# MOTOR register map
Registers are 32-bit, access not given, no defined reset value unless marked. A register's access mark holds for its fields unless they carry their own. Addresses are absolute; registers are grouped by the start of their names; [hi:lo] are bit positions; {n}, {i} and the like mark numbered series.

## FILTER
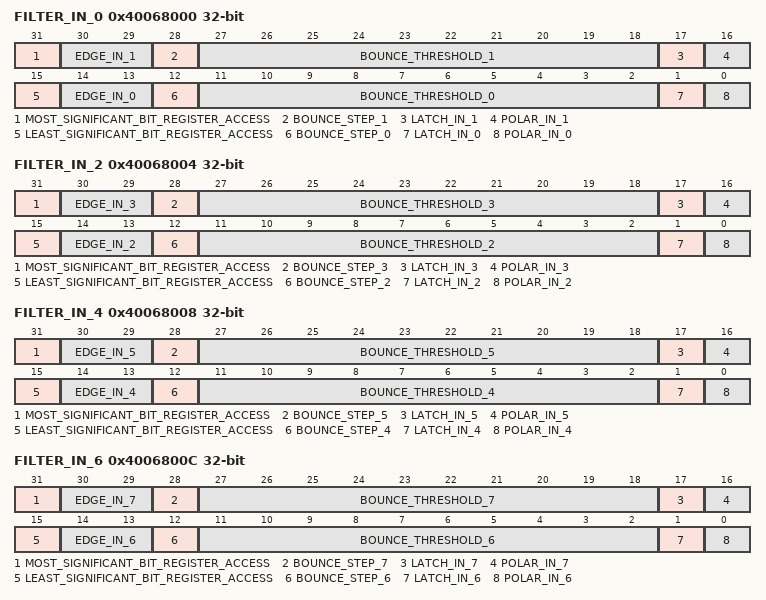
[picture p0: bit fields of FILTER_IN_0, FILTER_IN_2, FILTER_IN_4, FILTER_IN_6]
0x40068000 FILTER_IN_0
  [31] MOST_SIGNIFICANT_BIT_REGISTER_ACCESS, [30:29] EDGE_IN_1, [28] BOUNCE_STEP_1, [27:18] BOUNCE_THRESHOLD_1, [17] LATCH_IN_1, [16] POLAR_IN_1, [15] LEAST_SIGNIFICANT_BIT_REGISTER_ACCESS, [14:13] EDGE_IN_0, [12] BOUNCE_STEP_0, [11:2] BOUNCE_THRESHOLD_0, [1] LATCH_IN_0, [0] POLAR_IN_0
0x40068004 FILTER_IN_2
  [31] MOST_SIGNIFICANT_BIT_REGISTER_ACCESS, [30:29] EDGE_IN_3, [28] BOUNCE_STEP_3, [27:18] BOUNCE_THRESHOLD_3, [17] LATCH_IN_3, [16] POLAR_IN_3, [15] LEAST_SIGNIFICANT_BIT_REGISTER_ACCESS, [14:13] EDGE_IN_2, [12] BOUNCE_STEP_2, [11:2] BOUNCE_THRESHOLD_2, [1] LATCH_IN_2, [0] POLAR_IN_2
0x40068008 FILTER_IN_4
  [31] MOST_SIGNIFICANT_BIT_REGISTER_ACCESS, [30:29] EDGE_IN_5, [28] BOUNCE_STEP_5, [27:18] BOUNCE_THRESHOLD_5, [17] LATCH_IN_5, [16] POLAR_IN_5, [15] LEAST_SIGNIFICANT_BIT_REGISTER_ACCESS, [14:13] EDGE_IN_4, [12] BOUNCE_STEP_4, [11:2] BOUNCE_THRESHOLD_4, [1] LATCH_IN_4, [0] POLAR_IN_4
0x4006800C FILTER_IN_6
  [31] MOST_SIGNIFICANT_BIT_REGISTER_ACCESS, [30:29] EDGE_IN_7, [28] BOUNCE_STEP_7, [27:18] BOUNCE_THRESHOLD_7, [17] LATCH_IN_7, [16] POLAR_IN_7, [15] LEAST_SIGNIFICANT_BIT_REGISTER_ACCESS, [14:13] EDGE_IN_6, [12] BOUNCE_STEP_6, [11:2] BOUNCE_THRESHOLD_6, [1] LATCH_IN_6, [0] POLAR_IN_6
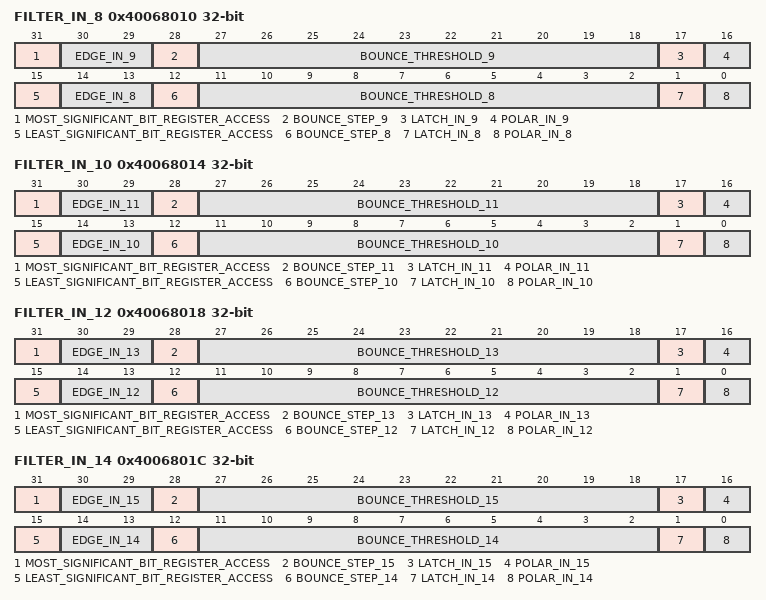
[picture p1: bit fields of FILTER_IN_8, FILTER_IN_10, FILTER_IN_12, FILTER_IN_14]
0x40068010 FILTER_IN_8
  [31] MOST_SIGNIFICANT_BIT_REGISTER_ACCESS, [30:29] EDGE_IN_9, [28] BOUNCE_STEP_9, [27:18] BOUNCE_THRESHOLD_9, [17] LATCH_IN_9, [16] POLAR_IN_9, [15] LEAST_SIGNIFICANT_BIT_REGISTER_ACCESS, [14:13] EDGE_IN_8, [12] BOUNCE_STEP_8, [11:2] BOUNCE_THRESHOLD_8, [1] LATCH_IN_8, [0] POLAR_IN_8
0x40068014 FILTER_IN_10
  [31] MOST_SIGNIFICANT_BIT_REGISTER_ACCESS, [30:29] EDGE_IN_11, [28] BOUNCE_STEP_11, [27:18] BOUNCE_THRESHOLD_11, [17] LATCH_IN_11, [16] POLAR_IN_11, [15] LEAST_SIGNIFICANT_BIT_REGISTER_ACCESS, [14:13] EDGE_IN_10, [12] BOUNCE_STEP_10, [11:2] BOUNCE_THRESHOLD_10, [1] LATCH_IN_10, [0] POLAR_IN_10
0x40068018 FILTER_IN_12
  [31] MOST_SIGNIFICANT_BIT_REGISTER_ACCESS, [30:29] EDGE_IN_13, [28] BOUNCE_STEP_13, [27:18] BOUNCE_THRESHOLD_13, [17] LATCH_IN_13, [16] POLAR_IN_13, [15] LEAST_SIGNIFICANT_BIT_REGISTER_ACCESS, [14:13] EDGE_IN_12, [12] BOUNCE_STEP_12, [11:2] BOUNCE_THRESHOLD_12, [1] LATCH_IN_12, [0] POLAR_IN_12
0x4006801C FILTER_IN_14
  [31] MOST_SIGNIFICANT_BIT_REGISTER_ACCESS, [30:29] EDGE_IN_15, [28] BOUNCE_STEP_15, [27:18] BOUNCE_THRESHOLD_15, [17] LATCH_IN_15, [16] POLAR_IN_15, [15] LEAST_SIGNIFICANT_BIT_REGISTER_ACCESS, [14:13] EDGE_IN_14, [12] BOUNCE_STEP_14, [11:2] BOUNCE_THRESHOLD_14, [1] LATCH_IN_14, [0] POLAR_IN_14
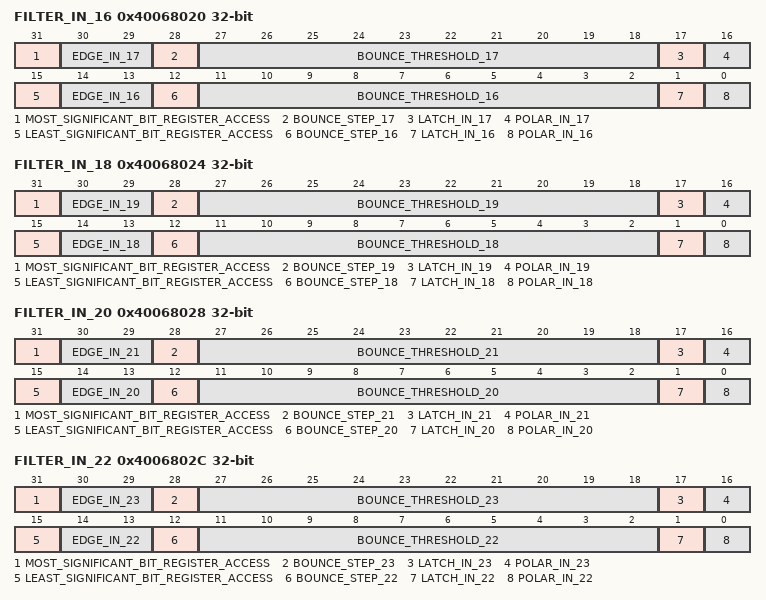
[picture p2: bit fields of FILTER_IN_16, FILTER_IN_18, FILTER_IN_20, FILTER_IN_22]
0x40068020 FILTER_IN_16
  [31] MOST_SIGNIFICANT_BIT_REGISTER_ACCESS, [30:29] EDGE_IN_17, [28] BOUNCE_STEP_17, [27:18] BOUNCE_THRESHOLD_17, [17] LATCH_IN_17, [16] POLAR_IN_17, [15] LEAST_SIGNIFICANT_BIT_REGISTER_ACCESS, [14:13] EDGE_IN_16, [12] BOUNCE_STEP_16, [11:2] BOUNCE_THRESHOLD_16, [1] LATCH_IN_16, [0] POLAR_IN_16
0x40068024 FILTER_IN_18
  [31] MOST_SIGNIFICANT_BIT_REGISTER_ACCESS, [30:29] EDGE_IN_19, [28] BOUNCE_STEP_19, [27:18] BOUNCE_THRESHOLD_19, [17] LATCH_IN_19, [16] POLAR_IN_19, [15] LEAST_SIGNIFICANT_BIT_REGISTER_ACCESS, [14:13] EDGE_IN_18, [12] BOUNCE_STEP_18, [11:2] BOUNCE_THRESHOLD_18, [1] LATCH_IN_18, [0] POLAR_IN_18
0x40068028 FILTER_IN_20
  [31] MOST_SIGNIFICANT_BIT_REGISTER_ACCESS, [30:29] EDGE_IN_21, [28] BOUNCE_STEP_21, [27:18] BOUNCE_THRESHOLD_21, [17] LATCH_IN_21, [16] POLAR_IN_21, [15] LEAST_SIGNIFICANT_BIT_REGISTER_ACCESS, [14:13] EDGE_IN_20, [12] BOUNCE_STEP_20, [11:2] BOUNCE_THRESHOLD_20, [1] LATCH_IN_20, [0] POLAR_IN_20
0x4006802C FILTER_IN_22
  [31] MOST_SIGNIFICANT_BIT_REGISTER_ACCESS, [30:29] EDGE_IN_23, [28] BOUNCE_STEP_23, [27:18] BOUNCE_THRESHOLD_23, [17] LATCH_IN_23, [16] POLAR_IN_23, [15] LEAST_SIGNIFICANT_BIT_REGISTER_ACCESS, [14:13] EDGE_IN_22, [12] BOUNCE_STEP_22, [11:2] BOUNCE_THRESHOLD_22, [1] LATCH_IN_22, [0] POLAR_IN_22
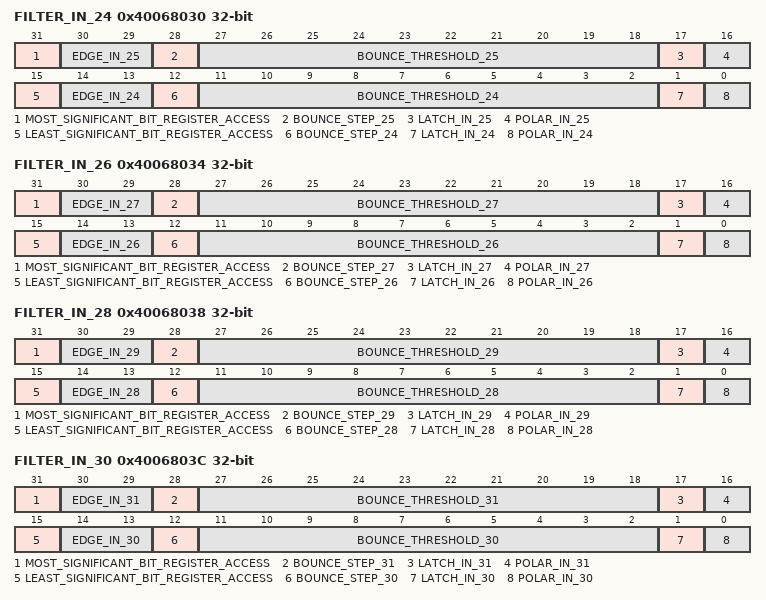
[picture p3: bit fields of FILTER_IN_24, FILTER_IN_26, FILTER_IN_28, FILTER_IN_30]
0x40068030 FILTER_IN_24
  [31] MOST_SIGNIFICANT_BIT_REGISTER_ACCESS, [30:29] EDGE_IN_25, [28] BOUNCE_STEP_25, [27:18] BOUNCE_THRESHOLD_25, [17] LATCH_IN_25, [16] POLAR_IN_25, [15] LEAST_SIGNIFICANT_BIT_REGISTER_ACCESS, [14:13] EDGE_IN_24, [12] BOUNCE_STEP_24, [11:2] BOUNCE_THRESHOLD_24, [1] LATCH_IN_24, [0] POLAR_IN_24
0x40068034 FILTER_IN_26
  [31] MOST_SIGNIFICANT_BIT_REGISTER_ACCESS, [30:29] EDGE_IN_27, [28] BOUNCE_STEP_27, [27:18] BOUNCE_THRESHOLD_27, [17] LATCH_IN_27, [16] POLAR_IN_27, [15] LEAST_SIGNIFICANT_BIT_REGISTER_ACCESS, [14:13] EDGE_IN_26, [12] BOUNCE_STEP_26, [11:2] BOUNCE_THRESHOLD_26, [1] LATCH_IN_26, [0] POLAR_IN_26
0x40068038 FILTER_IN_28
  [31] MOST_SIGNIFICANT_BIT_REGISTER_ACCESS, [30:29] EDGE_IN_29, [28] BOUNCE_STEP_29, [27:18] BOUNCE_THRESHOLD_29, [17] LATCH_IN_29, [16] POLAR_IN_29, [15] LEAST_SIGNIFICANT_BIT_REGISTER_ACCESS, [14:13] EDGE_IN_28, [12] BOUNCE_STEP_28, [11:2] BOUNCE_THRESHOLD_28, [1] LATCH_IN_28, [0] POLAR_IN_28
0x4006803C FILTER_IN_30
  [31] MOST_SIGNIFICANT_BIT_REGISTER_ACCESS, [30:29] EDGE_IN_31, [28] BOUNCE_STEP_31, [27:18] BOUNCE_THRESHOLD_31, [17] LATCH_IN_31, [16] POLAR_IN_31, [15] LEAST_SIGNIFICANT_BIT_REGISTER_ACCESS, [14:13] EDGE_IN_30, [12] BOUNCE_STEP_30, [11:2] BOUNCE_THRESHOLD_30, [1] LATCH_IN_30, [0] POLAR_IN_30
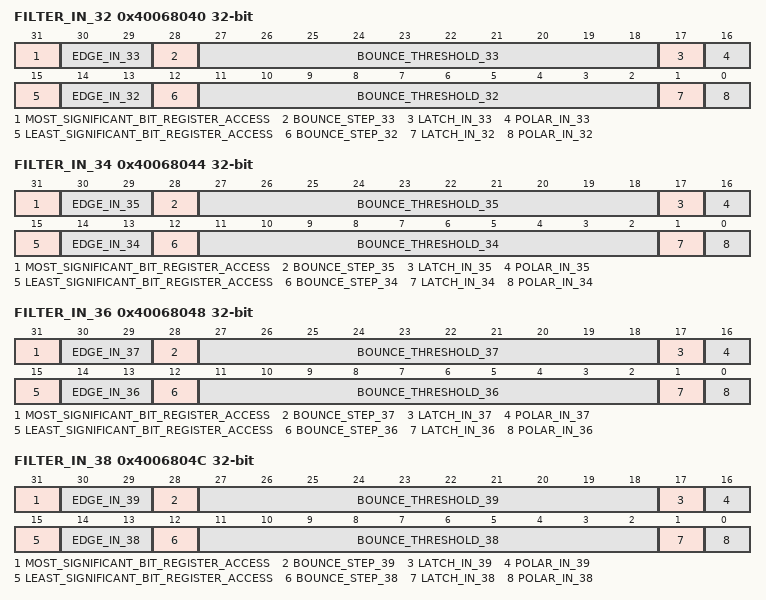
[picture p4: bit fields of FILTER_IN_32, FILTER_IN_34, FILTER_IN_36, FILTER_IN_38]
0x40068040 FILTER_IN_32
  [31] MOST_SIGNIFICANT_BIT_REGISTER_ACCESS, [30:29] EDGE_IN_33, [28] BOUNCE_STEP_33, [27:18] BOUNCE_THRESHOLD_33, [17] LATCH_IN_33, [16] POLAR_IN_33, [15] LEAST_SIGNIFICANT_BIT_REGISTER_ACCESS, [14:13] EDGE_IN_32, [12] BOUNCE_STEP_32, [11:2] BOUNCE_THRESHOLD_32, [1] LATCH_IN_32, [0] POLAR_IN_32
0x40068044 FILTER_IN_34
  [31] MOST_SIGNIFICANT_BIT_REGISTER_ACCESS, [30:29] EDGE_IN_35, [28] BOUNCE_STEP_35, [27:18] BOUNCE_THRESHOLD_35, [17] LATCH_IN_35, [16] POLAR_IN_35, [15] LEAST_SIGNIFICANT_BIT_REGISTER_ACCESS, [14:13] EDGE_IN_34, [12] BOUNCE_STEP_34, [11:2] BOUNCE_THRESHOLD_34, [1] LATCH_IN_34, [0] POLAR_IN_34
0x40068048 FILTER_IN_36
  [31] MOST_SIGNIFICANT_BIT_REGISTER_ACCESS, [30:29] EDGE_IN_37, [28] BOUNCE_STEP_37, [27:18] BOUNCE_THRESHOLD_37, [17] LATCH_IN_37, [16] POLAR_IN_37, [15] LEAST_SIGNIFICANT_BIT_REGISTER_ACCESS, [14:13] EDGE_IN_36, [12] BOUNCE_STEP_36, [11:2] BOUNCE_THRESHOLD_36, [1] LATCH_IN_36, [0] POLAR_IN_36
0x4006804C FILTER_IN_38
  [31] MOST_SIGNIFICANT_BIT_REGISTER_ACCESS, [30:29] EDGE_IN_39, [28] BOUNCE_STEP_39, [27:18] BOUNCE_THRESHOLD_39, [17] LATCH_IN_39, [16] POLAR_IN_39, [15] LEAST_SIGNIFICANT_BIT_REGISTER_ACCESS, [14:13] EDGE_IN_38, [12] BOUNCE_STEP_38, [11:2] BOUNCE_THRESHOLD_38, [1] LATCH_IN_38, [0] POLAR_IN_38
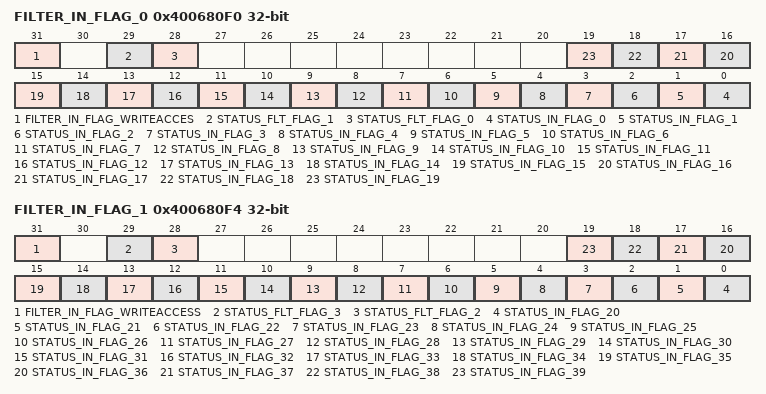
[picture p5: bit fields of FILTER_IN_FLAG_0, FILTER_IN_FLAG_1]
0x400680F0 FILTER_IN_FLAG_0
  [31] FILTER_IN_FLAG_WRITEACCES, [29] STATUS_FLT_FLAG_1, [28] STATUS_FLT_FLAG_0, [n] STATUS_IN_FLAG_{n} (n=0..19)
0x400680F4 FILTER_IN_FLAG_1
  [31] FILTER_IN_FLAG_WRITEACCESS, [29] STATUS_FLT_FLAG_3, [28] STATUS_FLT_FLAG_2, [n-20] STATUS_IN_FLAG_{n} (n=20..39)
